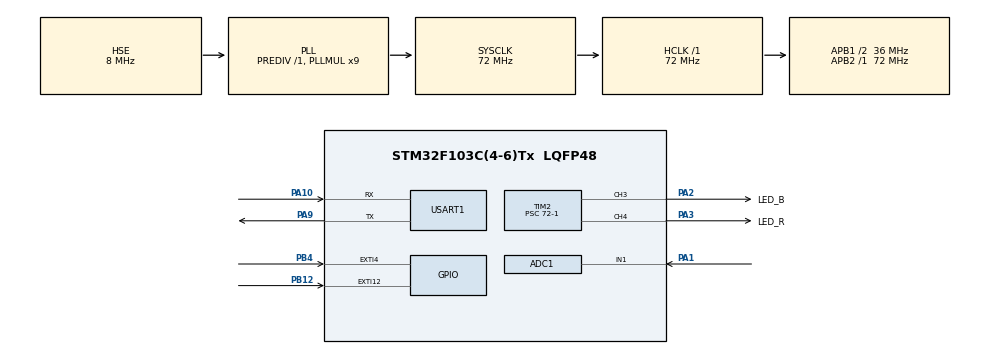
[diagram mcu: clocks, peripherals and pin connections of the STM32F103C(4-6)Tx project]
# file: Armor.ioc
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ADC1.Channel-0\#ChannelRegularConversion=ADC_CHANNEL_1
ADC1.NbrOfConversionFlag=1
ADC1.Rank-0\#ChannelRegularConversion=1
ADC1.SamplingTime-0\#ChannelRegularConversion=ADC_SAMPLETIME_1CYCLE_5
ADC1.master=1
Dma.Request0=USART1_RX
Dma.USART1_RX.0.Direction=DMA_PERIPH_TO_MEMORY
Dma.USART1_RX.0.Instance=DMA1_Channel5
Dma.USART1_RX.0.MemDataAlignment=DMA_MDATAALIGN_BYTE
Dma.USART1_RX.0.MemInc=DMA_MINC_ENABLE
Dma.USART1_RX.0.Mode=DMA_NORMAL
Dma.USART1_RX.0.PeriphDataAlignment=DMA_PDATAALIGN_BYTE
Dma.USART1_RX.0.PeriphInc=DMA_PINC_DISABLE
Dma.USART1_RX.0.Priority=DMA_PRIORITY_LOW
Mcu.Family=STM32F1
Mcu.Name=STM32F103C(4-6)Tx
Mcu.Package=LQFP48
NVIC.DMA1_Channel5_IRQn=true\:0\:0\:false\:false\:true\:false\:true\:true
NVIC.EXTI15_10_IRQn=true\:0\:0\:false\:false\:true\:true\:true\:true
NVIC.EXTI4_IRQn=true\:0\:0\:false\:false\:true\:true\:true\:true
NVIC.PriorityGroup=NVIC_PRIORITYGROUP_4
NVIC.TIM1_UP_IRQn=true\:0\:0\:false\:false\:true\:true\:true\:true
NVIC.USART1_IRQn=true\:0\:0\:false\:false\:true\:true\:true\:true
PA1.Signal=ADCx_IN1
PA10.Mode=Asynchronous
PA10.Signal=USART1_RX
PA13.Mode=Serial_Wire
PA13.Signal=SYS_JTMS-SWDIO
PA14.Mode=Serial_Wire
PA14.Signal=SYS_JTCK-SWCLK
PA2.GPIO_Label=LED_B
PA2.Signal=S_TIM2_CH3
PA3.GPIO_Label=LED_R
PA3.Signal=S_TIM2_CH4
PA9.Mode=Asynchronous
PA9.Signal=USART1_TX
PB12.Signal=GPXTI12
PB4.GPIO_PuPd=GPIO_NOPULL
PB4.Signal=GPXTI4
PD0-OSC_IN.Mode=HSE-External-Oscillator
PD0-OSC_IN.Signal=RCC_OSC_IN
PD1-OSC_OUT.Mode=HSE-External-Oscillator
PD1-OSC_OUT.Signal=RCC_OSC_OUT
ProjectManager.HeapSize=0x200
ProjectManager.StackSize=0x400
ProjectManager.TargetToolchain=STM32CubeIDE
RCC.ADCPresc=RCC_ADCPCLK2_DIV6
RCC.AHBFreq_Value=72000000
RCC.APB1CLKDivider=RCC_HCLK_DIV2
RCC.APB1Freq_Value=36000000
RCC.APB1TimFreq_Value=72000000
RCC.APB2Freq_Value=72000000
RCC.APB2TimFreq_Value=72000000
RCC.HCLKFreq_Value=72000000
RCC.PLLMUL=RCC_PLL_MUL9
RCC.PLLSourceVirtual=RCC_PLLSOURCE_HSE
RCC.SYSCLKFreq_VALUE=72000000
RCC.SYSCLKSource=RCC_SYSCLKSOURCE_PLLCLK
RCC.USBFreq_Value=72000000
SH.ADCx_IN1.0=ADC1_IN1,IN1
SH.S_TIM2_CH3.0=TIM2_CH3,PWM Generation3 CH3
SH.S_TIM2_CH4.0=TIM2_CH4,PWM Generation4 CH4
TIM1.AutoReloadPreload=TIM_AUTORELOAD_PRELOAD_ENABLE
TIM1.Period=10000-1
TIM1.Prescaler=72-1
TIM2.AutoReloadPreload=TIM_AUTORELOAD_PRELOAD_ENABLE
TIM2.Channel-PWM\ Generation3\ CH3=TIM_CHANNEL_3
TIM2.Channel-PWM\ Generation4\ CH4=TIM_CHANNEL_4
TIM2.Period=100-1
TIM2.Prescaler=72-1
TIM3.Prescaler=72-1
USART1.VirtualMode=VM_ASYNC
VP_TIM1_VS_ClockSourceINT.Mode=Internal
VP_TIM2_VS_ClockSourceINT.Mode=Internal
VP_TIM3_VS_ClockSourceINT.Mode=Internal
board=custom

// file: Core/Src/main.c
/* USER CODE BEGIN Header */
/**
  ******************************************************************************
  * @file           : main.c
  * @brief          : Main program body
  ******************************************************************************
  * @attention
  *
  * Copyright (c) 2024 STMicroelectronics.
  * All rights reserved.
  *
  * This software is licensed under terms that can be found in the LICENSE file
  * in the root directory of this software component.
  * If no LICENSE file comes with this software, it is provided AS-IS.
  *
  ******************************************************************************
  */
/* USER CODE END Header */
#include "main.h"
#include "adc.h"
#include "dma.h"
#include "tim.h"
#include "usart.h"
#include "gpio.h"

/* USER CODE BEGIN Includes */
#include "bsp.h"
/* USER CODE END Includes */

void SystemClock_Config(void);

int main(void)
{

  /* MCU Configuration--------------------------------------------------------*/

  /* Reset of all peripherals, Initializes the Flash interface and the Systick. */
  HAL_Init();

  /* Configure the system clock */
  SystemClock_Config();

  /* Initialize all configured peripherals */
  MX_GPIO_Init();
  MX_DMA_Init();
  MX_ADC1_Init();
  MX_USART1_UART_Init();
  MX_TIM1_Init();
  MX_TIM2_Init();
  MX_TIM3_Init();
  /* USER CODE BEGIN 2 */
  HAL_UARTEx_ReceiveToIdle_DMA(&huart1, rx_buf, 128);
  __HAL_DMA_DISABLE_IT(huart1.hdmarx, DMA_IT_HT);
  HAL_TIM_Base_Start_IT(&htim1);
  HAL_TIM_PWM_Start(&htim2,TIM_CHANNEL_3);
  HAL_TIM_PWM_Start(&htim2,TIM_CHANNEL_4);
  __HAL_TIM_SET_COMPARE(&htim2,TIM_CHANNEL_3,0);
  __HAL_TIM_SET_COMPARE(&htim2,TIM_CHANNEL_4,0);
  //HAL_NVIC_EnableIRQ()；

  /* USER CODE END 2 */

  /* Infinite loop */
  while (1)
  {

  }
}

void SystemClock_Config(void)
{
  RCC_OscInitTypeDef RCC_OscInitStruct = {0};
  RCC_ClkInitTypeDef RCC_ClkInitStruct = {0};
  RCC_PeriphCLKInitTypeDef PeriphClkInit = {0};

  /** Initializes the RCC Oscillators according to the specified parameters
  * in the RCC_OscInitTypeDef structure.
  */
  RCC_OscInitStruct.OscillatorType = RCC_OSCILLATORTYPE_HSE;
  RCC_OscInitStruct.HSEState = RCC_HSE_ON;
  RCC_OscInitStruct.HSEPredivValue = RCC_HSE_PREDIV_DIV1;
  RCC_OscInitStruct.HSIState = RCC_HSI_ON;
  RCC_OscInitStruct.PLL.PLLState = RCC_PLL_ON;
  RCC_OscInitStruct.PLL.PLLSource = RCC_PLLSOURCE_HSE;
  RCC_OscInitStruct.PLL.PLLMUL = RCC_PLL_MUL9;
  if (HAL_RCC_OscConfig(&RCC_OscInitStruct) != HAL_OK)
  {
    Error_Handler();
  }

  /** Initializes the CPU, AHB and APB buses clocks
  */
  RCC_ClkInitStruct.ClockType = RCC_CLOCKTYPE_HCLK|RCC_CLOCKTYPE_SYSCLK
                              |RCC_CLOCKTYPE_PCLK1|RCC_CLOCKTYPE_PCLK2;
  RCC_ClkInitStruct.SYSCLKSource = RCC_SYSCLKSOURCE_PLLCLK;
  RCC_ClkInitStruct.AHBCLKDivider = RCC_SYSCLK_DIV1;
  RCC_ClkInitStruct.APB1CLKDivider = RCC_HCLK_DIV2;
  RCC_ClkInitStruct.APB2CLKDivider = RCC_HCLK_DIV1;

  if (HAL_RCC_ClockConfig(&RCC_ClkInitStruct, FLASH_LATENCY_2) != HAL_OK)
  {
    Error_Handler();
  }
  PeriphClkInit.PeriphClockSelection = RCC_PERIPHCLK_ADC;
  PeriphClkInit.AdcClockSelection = RCC_ADCPCLK2_DIV6;
  if (HAL_RCCEx_PeriphCLKConfig(&PeriphClkInit) != HAL_OK)
  {
    Error_Handler();
  }
}

void Error_Handler(void)
{
  __disable_irq();
  while (1)
  {
  }
}
